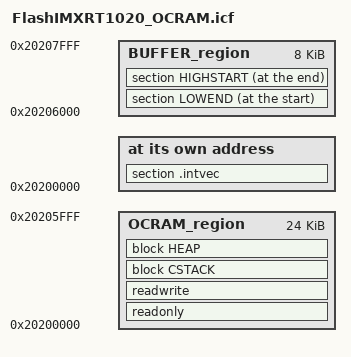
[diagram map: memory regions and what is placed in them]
/*###ICF### Section handled by ICF editor, don't touch! ****/
/*-Editor annotation file-*/
/* IcfEditorFile="$TOOLKIT_DIR$\config\ide\IcfEditor\cortex_v1_0.xml" */
/*-Specials-*/
define symbol __ICFEDIT_intvec_start__ = 0x20200000;
/*-Memory Regions-*/
define symbol __ICFEDIT_region_ROM_start__ = 0x00000000;
define symbol __ICFEDIT_region_ROM_end__   = 0x00000000;
define symbol __ICFEDIT_region_OCRAM_start__ = 0x20200000;
define symbol __ICFEDIT_region_OCRAM_end__   = 0x20205FFF;
define symbol __ICFEDIT_region_BUFFER_start__ = 0x20206000;
define symbol __ICFEDIT_region_BUFFER_end__   = 0x20207FFF;
/*-Sizes-*/
define symbol __ICFEDIT_size_cstack__ = 0x1000;
define symbol __ICFEDIT_size_heap__   = 0x100;
/**** End of ICF editor section. ###ICF###*/

define memory mem with size = 4G;
define region OCRAM_region  = mem:[from __ICFEDIT_region_OCRAM_start__   to __ICFEDIT_region_OCRAM_end__];
define region BUFFER_region  = mem:[from __ICFEDIT_region_BUFFER_start__   to __ICFEDIT_region_BUFFER_end__];

define block CSTACK    with alignment = 8, size = __ICFEDIT_size_cstack__   { };
define block HEAP      with alignment = 8, size = __ICFEDIT_size_heap__     { };

do not initialize { zi };

place at address mem:__ICFEDIT_intvec_start__ { section .intvec };

place in OCRAM_region { readonly };
place in OCRAM_region { readwrite, block CSTACK, block HEAP };
place at start of BUFFER_region {section LOWEND};
place at end of BUFFER_region   {section HIGHSTART};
